# RS1xxxx register map
Vendor: Silicon Lab Inc.; Series: ARMCM4; File version: 1.2
CPU: CM4 r1p0, little endian, MPU, FPU, 6 interrupt priority bits
Registers are 32-bit, read-write, reset 0x0 unless marked. A register's access mark holds for its fields unless they carry their own. Offsets are from the block's base; [hi:lo] are bit positions; {n}, {i} and the like mark numbered series.

## USART0 — Universal Asynchronous Receiver/Transmitter is for serial communication with peripherals, modems and datasets
Base 0x44000100
0x00 USART_DLL — Divisor Latch Low
  [7:0] DLL — Lower 8-bits of a 16-bit, read/write, Divisor Latch register that contains the baud rate divisor for the UART.
0x00 USART_THR wo (alternate view of DLL) — Transmit Holding Register
  [7:0] THR — Data to be transmitted on serial output port
0x00 USART_RBR ro (alternate view of DLL) — Receive Buffer Register
  [7:0] RBR — Receive Buffer Field
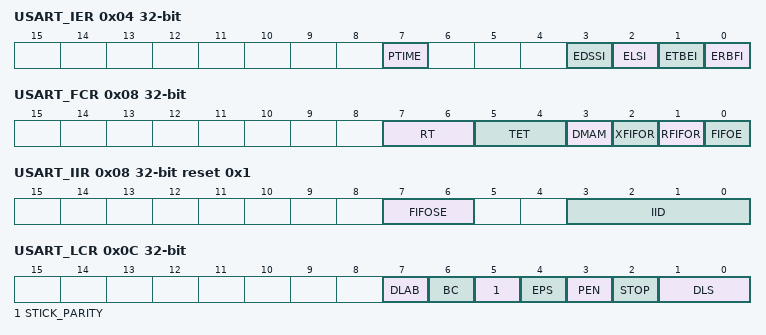
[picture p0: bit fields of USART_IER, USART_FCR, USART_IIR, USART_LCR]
0x04 USART_IER — Interrupt Enable Register
  [7] PTIME — Programmable THRE Interrupt Mode Enable
    0=Disable (generation of THRE Interrupt is disabled); 1=Enable (generation of THRE Interrupt is enabled)
  [3] EDSSI — Enable Modem Status Interrupt
    0=Disable (Modem Status Interrupt is disabled); 1=Enable (Modem Status Interrupt is enabled)
  [2] ELSI — Enable Receiver Line Status Interrupt
    0=Disable (Receiver Line Status Interrupt is disabled); 1=Enable (Receiver Line Status Interrupt is enabled)
  [1] ETBEI — Enable Transmit Holding Register Empty Interrupt
    0=Disable (Transmit Holding Register Empty Interrupt is disabled); 1=Enable (Transmit Holding Register Empty Interrupt is enabled)
  [0] ERBFI — Enable Received Data Available Interrupt
    0=Disable (Received Data Available Interrupt is disabled); 1=Enable (Received Data Available Interrupt is enabled)
0x04 USART_DLH (alternate view of IER) — Divisor Latch High
  [7:0] DLH — Upper 8-bits of a 16-bit, read/write, Divisor Latch register that contains the baud rate divisor for the UART
0x08 USART_FCR wo — FIFO Control Register
  [7:6] RT — This is used to select the trigger level in the receiver FIFO at which the Received Data Available Interrupt is generated
    0=FIFO_1_CHARACTER (1 character in the FIFO); 1=FIFO_1_BY_4_CHARACTER (FIFO 1/4 full); 2=FIFO_1_BY_2_CHARACTER (FIFO 1/2 full); 3=FIFO_LESS_THAN_2_CHARACTER (FIFO 2 less than full)
  [5:4] TET — TX Empty Trigger
    0=FIFO_EMPTY; 1=FIFO_2_CHARACTER (2 characters in the FIFO); 2=FIFO_1_BY_4_CHARACTER (FIFO 1/4 full); 3=FIFO_1_BY_2_CHARACTER (FIFO 1/2 full)
  [3] DMAM — DMA signalling mode
    0=Mode0 (DMA Signalling mode0); 1=Mode1 (DMA Signalling mode1)
  [2] XFIFOR — XMIT FIFO Reset
  [1] RFIFOR — RCVR FIFO Reset
  [0] FIFOE — This enables/disables the transmit (XMIT) and receive (RCVR) FIFOs
0x08 USART_IIR ro reset 0x1 — Interrupt Identity Register
  [7:6] FIFOSE — This is used to indicate whether the FIFOs are enabled or disabled.
    0=Disable (FIFO is disabled); 1=Enable (FIFO is enabled)
  [3:0] IID — Interrupt ID
    0=modem status pending pending interrupt; 1=This field indicates no interrupt pending status; 2=Transmit Holding Register Empty pending interrupt; 4=Received Data Available pending interrupt; 6=Receive line status pending interrupt; 7=Busy detect pending interrupt; 12=Character Timeout pending interrupt
0x0C USART_LCR — Line Control Register
  [7] DLAB — This bit is used to enable reading and writing of the Divisor Latch register to set the baud rate of the UART
    on write: 0=UNSET (This bit must be cleared after initial baud rate set up)
  [6] BC — This is used to cause a break condition to be transmitted to the receiving device
    1=SERIAL_OUTPUT_SPACING_STATE (If set to 1, the serial output is forced to the spacing (logic 0) state)
  [5] STICK_PARITY — This bit is used to force parity value
    0=LOGIC0 (When PEN, EPS, and Stick Parity are set to 1, the parity bit is transmitted and checked as logic 0); 1=LOGIC1 (If PEN and Stick Parity are set to 1 and EPS is a logic 0,then parity bit is transmitted and checked as a logic 1)
  [4] EPS — This is used to select between even and odd parity
    0=Set_to_0 (An odd number of logic 1s is transmitted or checked); 1=Set_to_1 (An even number of logic 1s is transmitted or checked)
  [3] PEN — This bit is used to enable and disable parity generation and detection in transmitted and received serial character
    0=Disable (Parity disabled); 1=Enable (Parity Enabled)
  [2] STOP — This is used to select the number of stop bits per character that the peripheral transmits and receives
    0=1_STOP_BIT_PER_CHARACTER; 1=1_5_OR_2_STOPS_BIT_PER_CHARACTER (1.5 or 2 stop bits per character)
  [1:0] DLS — Data Length Select,This is used to select the number of data bits per character that the peripheral transmits and receives
    {v}={v+5}_BITS_PER_CHARACTER (v=0..3)
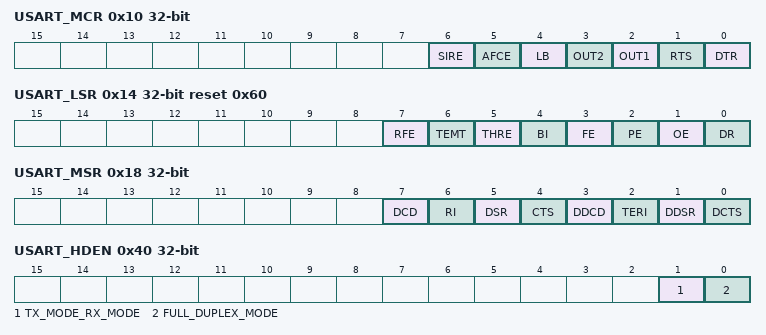
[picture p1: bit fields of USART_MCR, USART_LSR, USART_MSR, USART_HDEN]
0x10 USART_MCR — Modem Control Register
  [6] SIRE — This is used to enable/disable the IrDA SIR Mode features
    0=Disabled (IrDA SIR Mode disabled); 1=Enabled (IrDA SIR Mode enabled)
  [5] AFCE — This is used to directly control the user-designated Output2 (out2_n) output
    0=Disabled (Auto Flow Control Mode disabled); 1=Enabled (Auto Flow Control Mode enabled)
  [4] LB — This is used to put the UART into a diagnostic mode for test purposes
  [3] OUT2 — This is used to directly control the user-designated Output2 (out2_n) output
    0=OUT2_LOGIC1 (out2_n de-asserted (logic 1)); 1=OUT2_LOGIC0 (out2_n asserted (logic 0))
  [2] OUT1 — This is used to directly control the user-designated Output1 (out1_n) output
    0=OUT1_LOGIC1 (out1_n de-asserted (logic 1)); 1=OUT1_LOGIC0 (out1_n asserted (logic 0))
  [1] RTS — This is used to directly control the Request to Send (rts_n) output
  [0] DTR — This is used to directly control the Data Terminal Ready (dtr_n) output
    0=DTR_LOGIC1 (dtr_n de-asserted (logic 1)); 1=DTR_LOGIC0 (dtr_n asserted (logic 0))
0x14 USART_LSR ro reset 0x60 — Line Status Register
  [7] RFE — This is used to indicate if there is at least one parity error,framing error, or break indication in the FIFO
    on read: 0=Disabled (no error in RX FIFO); 1=Enabled (error in RX FIFO)
  [6] TEMT — Transmitter Empty bit
  [5] THRE — Transmit Holding Register Empty bit
  [4] BI — This is used to indicate the detection of a break sequence on the serial input data
  [3] FE — This is used to indicate the occurrence of a framing error in the receiver
    on read: 0=Disabled (no framing error); 1=Enabled (framing error)
  [2] PE — This is used to indicate the occurrence of a parity error in the receiver if the Parity Enable (PEN) bit (LCR[3]) is set
    on read: 0=Disabled (no parity error); 1=Enabled (parity error)
  [1] OE — This is used to indicate the occurrence of an overrun error
    on read: 0=Disabled (no overrun error); 1=Enabled (overrun error)
  [0] DR — This is used to indicate that the receiver contains at least one character in the RBR or the receiver FIFO
    on read: 0=Disabled (No data Ready); 1=Enabled (Data Ready)
0x18 USART_MSR ro — Modem Status Register
  [7] DCD — This is used to indicate the current state of the modem control line dcd_n
    on read: 0=Deasserted (dcd_n input is de-asserted (logic 1)); 1=Asserted (dcd_n input is asserted (logic 0))
  [6] RI — This is used to indicate the current state of the modem control line ri_n
    on read: 0=Deasserted (ri_n input is de-asserted (logic 1)); 1=Asserted (ri_n input is asserted (logic 0))
  [5] DSR — This is used to indicate the current state of the modem control line dsr_n
    on read: 0=Deasserted (dsr_n input is de-asserted (logic 1)); 1=Asserted (dsr_n input is asserted (logic 0))
  [4] CTS — This is used to indicate the current state of the modem control line cts_n
    on read: 0=Deasserted (cts_n input is de-asserted (logic 1)); 1=Asserted (cts_n input is asserted (logic 0))
  [3] DDCD — This is used to indicate that the modem control line dcd_n has changed since the last time the MSR was read
    on read: 0=no change on dcd_n since last read of MSR; 1=change on dcd_n since last read of MSR
  [2] TERI — This is used to indicate that a change on the input ri_n(from an active-low to an inactive-high state)has occurred since the last time the MSR was read
    on read: 0=no change on ri_n since last read of MSR; 1=change on ri_n since last read of MSR
  [1] DDSR — This is used to indicate that the modem control line dsr_n has changed since the last time the MSR was read
    on read: 0=no change on dsr_n since last read of MSR; 1=change on dsr_n since last read of MSR
  [0] DCTS — This is used to indicate that the modem control line cts_n has changed since the last time the MSR was read
    on read: 0=no change on cts_n since last read of MSR; 1=change on cts_n since last read of MSR
0x1C USART_SCR — Scratch pad Register
  [7:0] SCRATCH_PAD — This register is for programmers to use as a temporary storage space. It has no defined purpose
0x40 USART_HDEN — Hardware Enable register
  [1] TX_MODE_RX_MODE — This signal is valid when full_duplex_mode is disabled
    0=tx_mode; 1=rx_mode
  [0] FULL_DUPLEX_MODE
    1=ENABLE (Full duplex mode enable); 0=DISABLE (Full duplex mode disable)
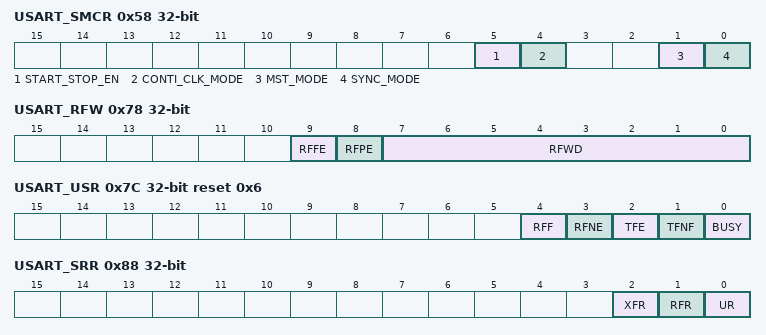
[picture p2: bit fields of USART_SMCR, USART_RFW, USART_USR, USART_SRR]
0x58 USART_SMCR — Control register
  [5] START_STOP_EN — start stop enable
    1=ENABLE_START_STOP; 0=DISABLE_START_STOP
  [4] CONTI_CLK_MODE
    1=CONTINUOUS_CLK_MODE (Continuous clock mode); 0=NON_CONTINUOUS_CLK_MODE (Non-continuous clock mode)
  [1] MST_MODE — Master Mode
    1=MST_MODE; 0=NON_MST_MODE
  [0] SYNC_MODE
    1=SYNC_MODE; 0=NON_SYNC_MODE
0x70 USART_FAR — FIFO Access Register
  [0] FIFO_Access — Enable fifo access mode
0x74 USART_TFR ro — Transmit FIFO Read Register
  [7:0] TX_FIFO_RD — Transmit FIFO Read
0x78 USART_RFW — Receive FIFO Write Register
  [9] RFFE wo — Receive FIFO Framing Error
  [8] RFPE wo — Receive FIFO Parity Error
  [7:0] RFWD wo — Receive FIFO Write Data
0x7C USART_USR ro reset 0x6 — UART Status Register
  [4] RFF — To Indicate that the receive FIFO is completely full
    on read: 0=Disabled (Receive FIFO not full); 1=Enabled (Receive FIFO Full)
  [3] RFNE — To Indicate that the receive FIFO contains one or more entries
    on read: 0=Disabled (Receive FIFO is empty); 1=Enabled (Receive FIFO is not empty)
  [2] TFE — To Indicate that the transmit FIFO is completely empty
    on read: 0=Disabled (Transmit FIFO is not empty); 1=Enabled (Transmit FIFO is empty)
  [1] TFNF — To Indicate that the transmit FIFO is not full
    on read: 0=Disabled (Transmit FIFO is full); 1=Enabled (Transmit FIFO is not full)
  [0] BUSY — Indicates that a serial transfer is in progress
    on read: 0=Disabled (UART is idle or inactive); 1=Enabled (UART is busy (actively transferring data))
0x80 USART_TFL ro — Transmit FIFO Level
  [29:0] Transmit_FIFO_Level — This is indicates the number of data entries in the transmit FIFO.
0x84 USART_RFL ro — Receive FIFO Level
  [29:0] Recieve_FIFO_Level — This is indicates the number of data entries in the receive FIFO.
0x88 USART_SRR wo — Software Reset Register
  [2] XFR — XMIT FIFO Reset
  [1] RFR — RCVR FIFO Reset
  [0] UR — UART Reset
0x8C USART_SRTS — Shadow Request to Send
  [0] SRTS — Shadow Request to Send.
0x90 USART_SBCR — Shadow Break Control Register
  [0] SBCR — Shadow Break Control Bit
0x94 USART_SDMAM — Shadow DMA Mode
  [0] SDMAM
    0=MODE0; 1=MODE1
0x98 USART_SFE — Shadow FIFO Enable
  [0] SFE
0x9C USART_SRT — Shadow RCVR Trigger
  [1:0] SRT
0xA0 USART_STET — Shadow TX Empty Trigger
  [1:0] STET
0xA4 USART_HTX — Halt Transmit
  [0] HALT_TX — This register is use to halt transmissions for testing
    0=Disabled (Halt TX disabled); 1=Enabled (Halt TX enabled)
0xA8 USART_DMASA — DMA Software Acknowledge
  [0] DMA_SOFTWARE_ACK wo — This register is use to perform a DMA software acknowledge if a transfer needs to be terminated due to an error condition
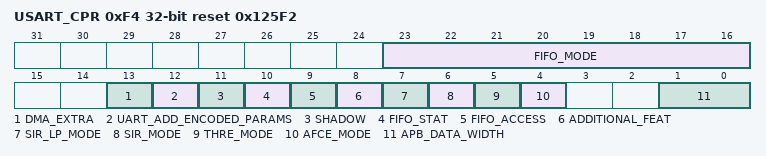
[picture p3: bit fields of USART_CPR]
0xF4 USART_CPR ro reset 0x125F2 — Component Parameter Register
  [23:16] FIFO_MODE
    on read: 1=TRUE; 0=FALSE
  [13] DMA_EXTRA
    on read: 1=TRUE; 0=FALSE
  [12] UART_ADD_ENCODED_PARAMS
    on read: 1=TRUE; 0=FALSE
  [11] SHADOW
    on read: 1=TRUE; 0=FALSE
  [10] FIFO_STAT
    on read: 1=TRUE; 0=FALSE
  [9] FIFO_ACCESS
    on read: 1=TRUE; 0=FALSE
  [8] ADDITIONAL_FEAT
    on read: 1=TRUE; 0=FALSE
  [7] SIR_LP_MODE
    on read: 1=TRUE; 0=FALSE
  [6] SIR_MODE
    on read: 1=TRUE; 0=FALSE
  [5] THRE_MODE
    on read: 1=TRUE; 0=FALSE
  [4] AFCE_MODE
    on read: 1=TRUE; 0=FALSE
  [1:0] APB_DATA_WIDTH
    on read: 0=8_BIT (APB Data Width 8 BIT); 1=16_BIT (APB Data Width 16 BIT); 2=32_BIT (APB Data Width 32 BIT)
0xF8 UCV ro reset 0x3430302A — UART Component Version
  [31:0] UART_COMP_VER — ASCII value for each number in the version, followed by *
0xFC USART_CTR ro reset 0x44570110 — Component Type Register
  [31:0] UART_COMP_VER — This register contains the peripherals identification code.
